# ddr32ss_EMIF_CTLCFG_0F308000h register map
Vendor: Texas Instruments
Registers are 32-bit, read-write, reset 0x0 unless marked. A register's access mark holds for its fields unless they carry their own. Offsets are as the file gives them; [hi:lo] are bit positions; {n}, {i} and the like mark numbered series.

## emif_ctlcfg (part 12 of 13)
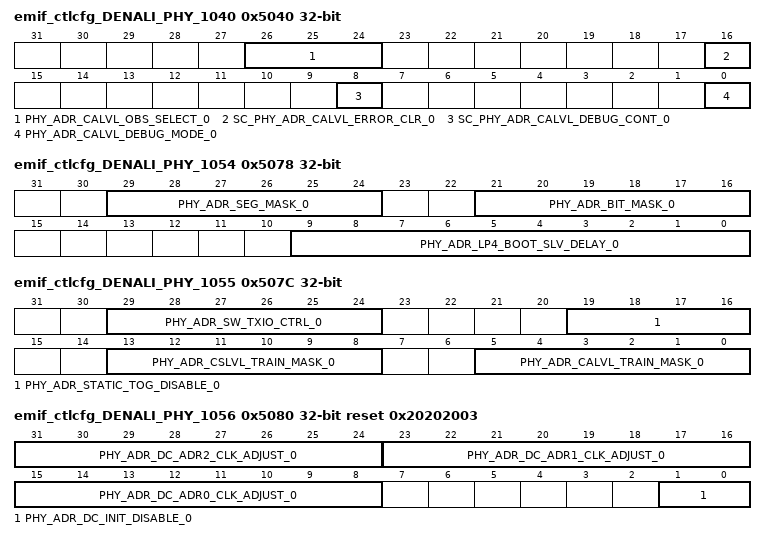
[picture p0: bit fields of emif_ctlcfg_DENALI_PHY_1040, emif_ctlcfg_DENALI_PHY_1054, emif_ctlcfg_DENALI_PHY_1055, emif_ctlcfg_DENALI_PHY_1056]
0x5040 emif_ctlcfg_DENALI_PHY_1040 access per field
  [26:24] PHY_ADR_CALVL_OBS_SELECT_0 rw — CA bit lane to observe result from OBS0 during CA training for address slice 0. Reset Source: ctl_amod_g_rst_n
  [16] SC_PHY_ADR_CALVL_ERROR_CLR_0 wo — Clears the CA training state machine error status for address slice 0. Set to 1 to trigger. WRITE-ONLY Reset Source: ctl_amod_g_rst_n
  [8] SC_PHY_ADR_CALVL_DEBUG_CONT_0 wo — Allows the CA training state machine to advance [when in debug mode] for address slice 0. Set to 1 to trigger. WRITE-ONLY Reset Source: ctl_amod_g_rst_n
  [0] PHY_ADR_CALVL_DEBUG_MODE_0 rw — Enables CA training debug mode for address slice 0. Set to 1 to enable. Reset Source: ctl_amod_g_rst_n
0x5044 emif_ctlcfg_DENALI_PHY_1041 ro
  [31:0] PHY_ADR_CALVL_CH0_OBS0_0 — Observation register for CA training for channel 0 slice 0. READ-ONLY Reset Source: ctl_amod_g_rst_n
0x5048 emif_ctlcfg_DENALI_PHY_1042 ro
  [31:0] PHY_ADR_CALVL_CH1_OBS0_0 — Observation register for CA training for channel 1 slice 0. READ-ONLY Reset Source: ctl_amod_g_rst_n
0x504C emif_ctlcfg_DENALI_PHY_1043 ro
  [31:0] PHY_ADR_CALVL_OBS1_0 — Observation register contains general CA training bits for slice 0. READ-ONLY Reset Source: ctl_amod_g_rst_n
0x5050 emif_ctlcfg_DENALI_PHY_1044 ro reset 0x100
  [31:0] PHY_ADR_CALVL_OBS2_0 — Observation register contains periodic CA training bits for slice 0. READ-ONLY Reset Source: ctl_amod_g_rst_n
0x5054 emif_ctlcfg_DENALI_PHY_1045
  [19:0] PHY_ADR_CALVL_FG_0_0 — CA training foreground pattern 0 for address slice 0. Reset Source: ctl_amod_g_rst_n
0x5058 emif_ctlcfg_DENALI_PHY_1046
  [19:0] PHY_ADR_CALVL_BG_0_0 — CA training background pattern 0 for address slice 0. Reset Source: ctl_amod_g_rst_n
0x505C emif_ctlcfg_DENALI_PHY_1047
  [19:0] PHY_ADR_CALVL_FG_1_0 — CA training foreground pattern 1 for address slice 0. Reset Source: ctl_amod_g_rst_n
0x5060 emif_ctlcfg_DENALI_PHY_1048
  [19:0] PHY_ADR_CALVL_BG_1_0 — CA training background pattern 1 for address slice 0. Reset Source: ctl_amod_g_rst_n
0x5064 emif_ctlcfg_DENALI_PHY_1049
  [19:0] PHY_ADR_CALVL_FG_2_0 — CA training foreground pattern 2 for address slice 0. Reset Source: ctl_amod_g_rst_n
0x5068 emif_ctlcfg_DENALI_PHY_1050
  [19:0] PHY_ADR_CALVL_BG_2_0 — CA training background pattern 2 for address slice 0. Reset Source: ctl_amod_g_rst_n
0x506C emif_ctlcfg_DENALI_PHY_1051
  [19:0] PHY_ADR_CALVL_FG_3_0 — CA training foreground pattern 3 for address slice 0. Reset Source: ctl_amod_g_rst_n
0x5070 emif_ctlcfg_DENALI_PHY_1052
  [19:0] PHY_ADR_CALVL_BG_3_0 — CA training background pattern 3 for address slice 0. Reset Source: ctl_amod_g_rst_n
0x5074 emif_ctlcfg_DENALI_PHY_1053
  [29:0] PHY_ADR_ADDR_SEL_0 — Selects which DFI address pins connect to which CA pins for LPDDR3/4 for address slice 0. Reset Source: ctl_amod_g_rst_n
0x5078 emif_ctlcfg_DENALI_PHY_1054
  [29:24] PHY_ADR_SEG_MASK_0 — Segment mask bit for address slice 0. Set to 1 to indicate that the bit is either CA 4 or CA 9. Reset Source: ctl_amod_g_rst_n
  [21:16] PHY_ADR_BIT_MASK_0 — Mask bit for address slice 0. Set to 1 to indicate that the bit is used. Reset Source: ctl_amod_g_rst_n
  [9:0] PHY_ADR_LP4_BOOT_SLV_DELAY_0 — Address target delay setting during the LPDDR4 boot frequency operation for address slice 0. Reset Source: ctl_amod_g_rst_n
0x507C emif_ctlcfg_DENALI_PHY_1055
  [29:24] PHY_ADR_SW_TXIO_CTRL_0 — Controls address pad output enable for address slice 0. Set to 1 to disable output enable. Reset Source: ctl_amod_g_rst_n
  [19:16] PHY_ADR_STATIC_TOG_DISABLE_0 — Toggle control during static activity for address slice 0. Set bit to dsiable toggling, bit0: Write path delay line, bit1: Read path delay line, bit2: Read data path, bit3: clk_phy, bit4: master delay line. Reset Source: ctl_amod_g_rst_n
  [13:8] PHY_ADR_CSLVL_TRAIN_MASK_0 — Mask bit for CS training participation for address slice 0. Set to 1 to indicate that the bit is participating in CS training. Reset Source: ctl_amod_g_rst_n
  [5:0] PHY_ADR_CALVL_TRAIN_MASK_0 — Mask bit for CA training participation for address slice 0. Set to 1 to indicate that the bit is participating in CA training. Reset Source: ctl_amod_g_rst_n
0x5080 emif_ctlcfg_DENALI_PHY_1056 reset 0x20202003
  [31:24] PHY_ADR_DC_ADR2_CLK_ADJUST_0 — Adjust value of Clock Duty Cycle Adjuster lane 2 for address slice 0. Reset Source: ctl_amod_g_rst_n
  [23:16] PHY_ADR_DC_ADR1_CLK_ADJUST_0 — Adjust value of Clock Duty Cycle Adjuster lane 1 for address slice 0. Reset Source: ctl_amod_g_rst_n
  [15:8] PHY_ADR_DC_ADR0_CLK_ADJUST_0 — Adjust value of Clock Duty Cycle Adjuster lane 0 for address slice 0. Reset Source: ctl_amod_g_rst_n
  [1:0] PHY_ADR_DC_INIT_DISABLE_0 — Duty Cycle Corrector disable at initialization for address slice 0. Set to 1 to disable, bit [1] controls data path, bit [0] controls clock path. Reset Source: ctl_amod_g_rst_n
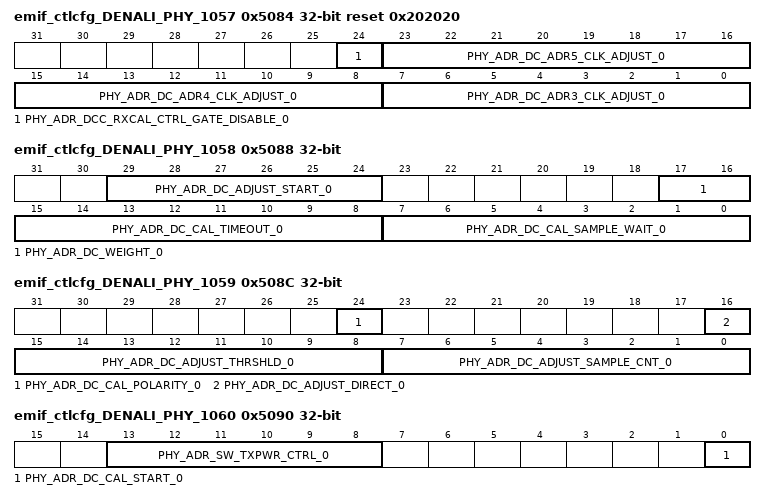
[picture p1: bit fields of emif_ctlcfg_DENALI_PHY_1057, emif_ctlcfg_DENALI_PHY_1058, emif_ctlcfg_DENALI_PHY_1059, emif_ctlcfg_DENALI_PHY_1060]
0x5084 emif_ctlcfg_DENALI_PHY_1057 reset 0x202020
  [24] PHY_ADR_DCC_RXCAL_CTRL_GATE_DISABLE_0 — DCC and RX_CAL clk gate disable for address slice 0. 1 = disable clk gate. Reset Source: ctl_amod_g_rst_n
  [23:16] PHY_ADR_DC_ADR5_CLK_ADJUST_0 — Adjust value of Clock Duty Cycle Adjuster lane 5 for address slice 0. Reset Source: ctl_amod_g_rst_n
  [15:8] PHY_ADR_DC_ADR4_CLK_ADJUST_0 — Adjust value of Clock Duty Cycle Adjuster lane 4 for address slice 0. Reset Source: ctl_amod_g_rst_n
  [7:0] PHY_ADR_DC_ADR3_CLK_ADJUST_0 — Adjust value of Clock Duty Cycle Adjuster lane 3 for address slice 0. Reset Source: ctl_amod_g_rst_n
0x5088 emif_ctlcfg_DENALI_PHY_1058
  [29:24] PHY_ADR_DC_ADJUST_START_0 — DCC calibration starting value for address slice 0. Reset Source: ctl_amod_g_rst_n
  [17:16] PHY_ADR_DC_WEIGHT_0 — DCC weighting factor base value for address slice 0. Reset Source: ctl_amod_g_rst_n
  [15:8] PHY_ADR_DC_CAL_TIMEOUT_0 — DCC number of iterations to wait before timeout for address slice 0. Reset Source: ctl_amod_g_rst_n
  [7:0] PHY_ADR_DC_CAL_SAMPLE_WAIT_0 — DCC cycles to wait after calibration change before sampling results for address slice 0. Reset Source: ctl_amod_g_rst_n
0x508C emif_ctlcfg_DENALI_PHY_1059
  [24] PHY_ADR_DC_CAL_POLARITY_0 — DCC calibration polarity for address slice 0. Reset Source: ctl_amod_g_rst_n
  [16] PHY_ADR_DC_ADJUST_DIRECT_0 — DCC adjust direction for address slice 0. Reset Source: ctl_amod_g_rst_n
  [15:8] PHY_ADR_DC_ADJUST_THRSHLD_0 — DCC adjust threshold around the mid-point for address slice 0. Reset Source: ctl_amod_g_rst_n
  [7:0] PHY_ADR_DC_ADJUST_SAMPLE_CNT_0 — DCC number of samples to take for address slice 0. Reset Source: ctl_amod_g_rst_n
0x5090 emif_ctlcfg_DENALI_PHY_1060
  [13:8] PHY_ADR_SW_TXPWR_CTRL_0 — Disable address output enables in deep sleep mode for address slice 0. Reset Source: ctl_amod_g_rst_n
  [0] PHY_ADR_DC_CAL_START_0 — DCC Manual trigger for address slice 0. Reset Source: ctl_amod_g_rst_n
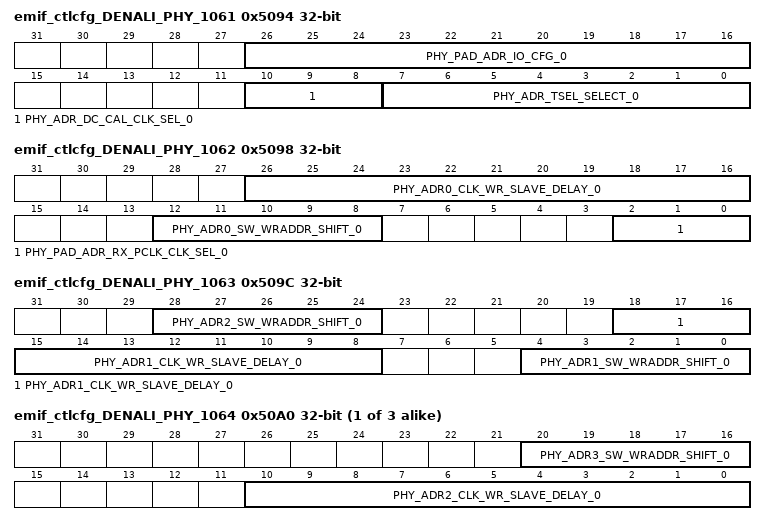
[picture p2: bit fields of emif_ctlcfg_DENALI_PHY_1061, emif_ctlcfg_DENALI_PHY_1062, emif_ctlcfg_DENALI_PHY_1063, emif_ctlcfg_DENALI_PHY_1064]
0x5094 emif_ctlcfg_DENALI_PHY_1061
  [26:16] PHY_PAD_ADR_IO_CFG_0 — Controls I/O pads for address pad for address slice 0. Bits [10:5] = Park value, bits [4] park override, bits [2:0] clk divider. Reset Source: ctl_amod_g_rst_n
  [10:8] PHY_ADR_DC_CAL_CLK_SEL_0 — DCC CAL clock for address slice 0. Reset Source: ctl_amod_g_rst_n
  [7:0] PHY_ADR_TSEL_SELECT_0 — Tsel select values for address slice 0. Reset Source: ctl_amod_g_rst_n
0x5098 emif_ctlcfg_DENALI_PHY_1062
  [26:16] PHY_ADR0_CLK_WR_SLAVE_DELAY_0 — CA bit 0 target delay setting for address slice 0. Reset Source: ctl_amod_g_rst_n
  [12:8] PHY_ADR0_SW_WRADDR_SHIFT_0 — Manual override of CA bit 0 of automatic half_cycle_shift/cycle_shift for address slice 0. Bit [0] enables override of half_cycle_shift. Bit [1] is the half_cycle_shift value. Bit [2] enables override of cycle shift. Bits [4:3] is the cycle_shift value. For bits [4:3], clear to 0x0 for no offset, program to 0x1 for -1 cycle, program to 0x2 for +1 cycle, or program to 0x3 for -2 cycles. Reset Source: ctl_amod_g_rst_n
  [2:0] PHY_PAD_ADR_RX_PCLK_CLK_SEL_0 — Reserved for address slice 0. Reset Source: ctl_amod_g_rst_n
0x509C emif_ctlcfg_DENALI_PHY_1063
  [28:24] PHY_ADR2_SW_WRADDR_SHIFT_0 — Manual override of CA bit 2 of automatic half_cycle_shift/cycle_shift for address slice 0. Bit [0] enables override of half_cycle_shift. Bit [1] is the half_cycle_shift value. Bit [2] enables override of cycle shift. Bits [4:3] is the cycle_shift value. For bits [4:3], clear to 0x0 for no offset, program to 0x1 for -1 cycle, program to 0x2 for +1 cycle, or program to 0x3 for -2 cycles. Reset Source: ctl_amod_g_rst_n
  [18:8] PHY_ADR1_CLK_WR_SLAVE_DELAY_0 — CA bit 1 target delay setting for address slice 0. Reset Source: ctl_amod_g_rst_n
  [4:0] PHY_ADR1_SW_WRADDR_SHIFT_0 — Manual override of CA bit 1 of automatic half_cycle_shift/cycle_shift for address slice 0. Bit [0] enables override of half_cycle_shift. Bit [1] is the half_cycle_shift value. Bit [2] enables override of cycle shift. Bits [4:3] is the cycle_shift value. For bits [4:3], clear to 0x0 for no offset, program to 0x1 for -1 cycle, program to 0x2 for +1 cycle, or program to 0x3 for -2 cycles. Reset Source: ctl_amod_g_rst_n
{0x4000+4i} emif_ctlcfg_DENALI_PHY_{i} (i=1064..1066)
  [20:16] PHY_ADR{i-1061}_SW_WRADDR_SHIFT_0 — Manual override of CA bit {i-1061} of automatic half_cycle_shift/cycle_shift for address slice 0. Bit [0] enables override of half_cycle_shift. Bit [1] is the half_cycle_shift value. Bit [2] enables override of cycle shift. Bits [4:3] is the cycle_shift value. For bits [4:3], clear to 0x0 for no offset, program to 0x1 for -1 cycle, program to 0x2 for +1 cycle, or program to 0x3 for -2 cycles. Reset Source: ctl_amod_g_rst_n
  [10:0] PHY_ADR{i-1062}_CLK_WR_SLAVE_DELAY_0 — CA bit {i-1062} target delay setting for address slice 0. Reset Source: ctl_amod_g_rst_n
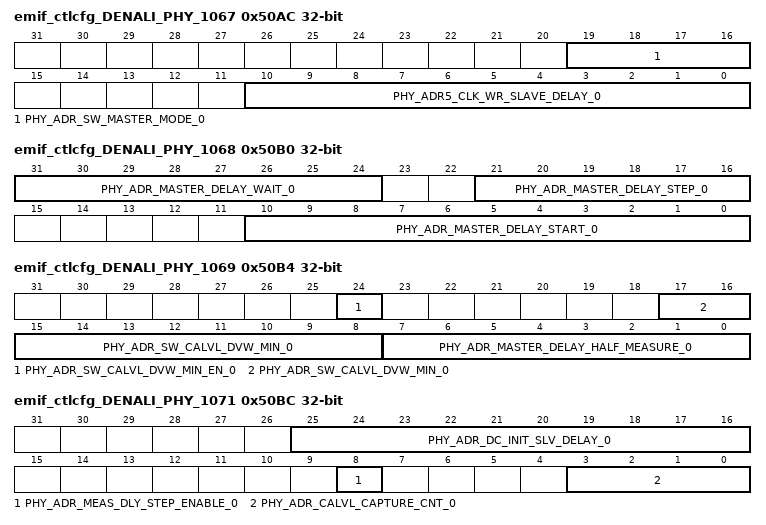
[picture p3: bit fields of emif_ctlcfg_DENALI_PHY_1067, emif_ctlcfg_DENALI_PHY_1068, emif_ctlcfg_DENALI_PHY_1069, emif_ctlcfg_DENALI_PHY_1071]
0x50AC emif_ctlcfg_DENALI_PHY_1067
  [19:16] PHY_ADR_SW_MASTER_MODE_0 — Master delay line override settings for address slice 0. Bit [0] enables software half clock mode. Bit [1] is the software half clock mode value. Bit [2] enables software bypass mode. Bit [3] is the software bypass mode value. Reset Source: ctl_amod_g_rst_n
  [10:0] PHY_ADR5_CLK_WR_SLAVE_DELAY_0 — CA bit 5 target delay setting for address slice 0. Reset Source: ctl_amod_g_rst_n
0x50B0 emif_ctlcfg_DENALI_PHY_1068
  [31:24] PHY_ADR_MASTER_DELAY_WAIT_0 — Wait cycles for master delay line locking algorithm for address slice 0. Bits [3:0] is the cycle wait count after a calibration clock setting change. Bits [7:4] is the cycle wait count after a master delay setting change. Reset Source: ctl_amod_g_rst_n
  [21:16] PHY_ADR_MASTER_DELAY_STEP_0 — Incremental step size for master delay line locking algorithm for address slice 0. Reset Source: ctl_amod_g_rst_n
  [10:0] PHY_ADR_MASTER_DELAY_START_0 — Start value for master delay line locking algorithm for address slice 0. Reset Source: ctl_amod_g_rst_n
0x50B4 emif_ctlcfg_DENALI_PHY_1069
  [24] PHY_ADR_SW_CALVL_DVW_MIN_EN_0 — Enables the software override data valid window size during CA training for address slice 0. Reset Source: ctl_amod_g_rst_n
  [17:8] PHY_ADR_SW_CALVL_DVW_MIN_0 — Sets the software override data valid window size during CA training for address slice 0. Reset Source: ctl_amod_g_rst_n
  [7:0] PHY_ADR_MASTER_DELAY_HALF_MEASURE_0 — Defines the number of delay line elements to be considered in determing whether to lock to a half clock cycle for the master in address slice 0 Reset Source: ctl_amod_g_rst_n
0x50B8 emif_ctlcfg_DENALI_PHY_1070
  [3:0] PHY_ADR_CALVL_DLY_STEP_0 — Sets the delay step size plus 1 during CA training for address slice 0. Reset Source: ctl_amod_g_rst_n
0x50BC emif_ctlcfg_DENALI_PHY_1071
  [25:16] PHY_ADR_DC_INIT_SLV_DELAY_0 — DCC initialization value of write ADDR target delay for address slice 0. Reset Source: ctl_amod_g_rst_n
  [8] PHY_ADR_MEAS_DLY_STEP_ENABLE_0 — Enables delay parameter setting using phy_adr_meas_dly_step_value for address slice 0. Reset Source: ctl_amod_g_rst_n
  [3:0] PHY_ADR_CALVL_CAPTURE_CNT_0 — Number of samples to take at each ADDR target delay setting during CA training for address slice 0. Reset Source: ctl_amod_g_rst_n
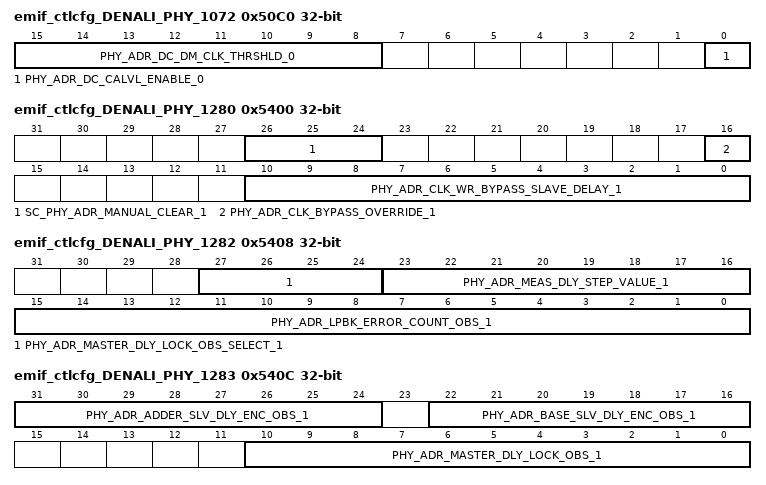
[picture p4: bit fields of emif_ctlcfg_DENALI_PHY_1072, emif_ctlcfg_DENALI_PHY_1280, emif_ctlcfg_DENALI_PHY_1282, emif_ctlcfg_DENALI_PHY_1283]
0x50C0 emif_ctlcfg_DENALI_PHY_1072
  [15:8] PHY_ADR_DC_DM_CLK_THRSHLD_0 — DCC clock measurement cell threshold offset for address slice 0. Reset Source: ctl_amod_g_rst_n
  [0] PHY_ADR_DC_CALVL_ENABLE_0 — DCC enable duty cycle adjust during CA leveling for address slice 0. Reset Source: ctl_amod_g_rst_n
0x5400 emif_ctlcfg_DENALI_PHY_1280 access per field
  [26:24] SC_PHY_ADR_MANUAL_CLEAR_1 wo — Manual reset/clear of internal logic for address slice 1. Bit [0] is reset of master delay min/max lock values. Bit [1] is manual reset of master delay unlock counter. Bit [2] clears the loopback error/results registers. Set each bit to 1 to reset. WRITE-ONLY Reset Source: ctl_amod_g_rst_n
  [16] PHY_ADR_CLK_BYPASS_OVERRIDE_1 rw — Bypass mode override setting for address slice 1. Set to 1 to enable. Reset Source: ctl_amod_g_rst_n
  [10:0] PHY_ADR_CLK_WR_BYPASS_SLAVE_DELAY_1 rw — Command/Address clock bypass mode target delay setting for address slice 1. Reset Source: ctl_amod_g_rst_n
0x5404 emif_ctlcfg_DENALI_PHY_1281 ro reset 0x1000
  [31:0] PHY_ADR_LPBK_RESULT_OBS_1 — Observation register containing loopback status/results for address slice 1. READ-ONLY Reset Source: ctl_amod_g_rst_n
0x5408 emif_ctlcfg_DENALI_PHY_1282 access per field
  [27:24] PHY_ADR_MASTER_DLY_LOCK_OBS_SELECT_1 rw — Select value to map the internal master delay observation registers to the accessible master delay observation register for address slice 1. Reset Source: ctl_amod_g_rst_n
  [23:16] PHY_ADR_MEAS_DLY_STEP_VALUE_1 ro — Contains the fraction of a cycle in 1 delay element numerator with demominator of 512, for address slice 1. READ-ONLY Reset Source: ctl_amod_g_rst_n
  [15:0] PHY_ADR_LPBK_ERROR_COUNT_OBS_1 ro — Observation register containing total number of loopback error data for address slice 1. READ-ONLY Reset Source: ctl_amod_g_rst_n
0x540C emif_ctlcfg_DENALI_PHY_1283 ro
  [31:24] PHY_ADR_ADDER_SLV_DLY_ENC_OBS_1 — Observation register containing addr target delay for address slice 1. READ-ONLY Reset Source: ctl_amod_g_rst_n
  [22:16] PHY_ADR_BASE_SLV_DLY_ENC_OBS_1 — Observation register containing base target delay for address slice 1. READ-ONLY Reset Source: ctl_amod_g_rst_n
  [10:0] PHY_ADR_MASTER_DLY_LOCK_OBS_1 — Observation register containing master delay results for address slice 1. READ-ONLY Reset Source: ctl_amod_g_rst_n
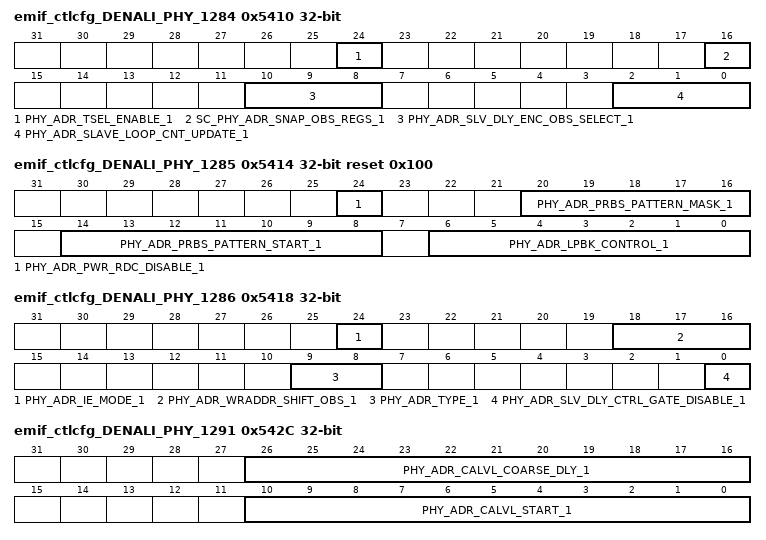
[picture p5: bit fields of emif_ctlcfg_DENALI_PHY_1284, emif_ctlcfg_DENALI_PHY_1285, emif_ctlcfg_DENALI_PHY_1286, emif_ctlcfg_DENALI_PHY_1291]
0x5410 emif_ctlcfg_DENALI_PHY_1284 access per field
  [24] PHY_ADR_TSEL_ENABLE_1 rw — Enables tsel_en for address slice 1. Reset Source: ctl_amod_g_rst_n
  [16] SC_PHY_ADR_SNAP_OBS_REGS_1 wo — Initiates a snapshot of the internal observation registers for address slice 1. Set to 1 to trigger. WRITE-ONLY Reset Source: ctl_amod_g_rst_n
  [10:8] PHY_ADR_SLV_DLY_ENC_OBS_SELECT_1 rw — Select value to map the addr bits delay observation registers to the accessible delay observation register for address slice 1. Reset Source: ctl_amod_g_rst_n
  [2:0] PHY_ADR_SLAVE_LOOP_CNT_UPDATE_1 rw — Reserved for address slice 1. Reset Source: ctl_amod_g_rst_n
0x5414 emif_ctlcfg_DENALI_PHY_1285 reset 0x100
  [24] PHY_ADR_PWR_RDC_DISABLE_1 — Power reduction disable for address slice 1. Reset Source: ctl_amod_g_rst_n
  [20:16] PHY_ADR_PRBS_PATTERN_MASK_1 — PRBS7 mask signal for address slice 1. Reset Source: ctl_amod_g_rst_n
  [14:8] PHY_ADR_PRBS_PATTERN_START_1 — PRBS7 start pattern for address slice 1. Reset Source: ctl_amod_g_rst_n
  [6:0] PHY_ADR_LPBK_CONTROL_1 — Loopback control bits for address slice 1. Reset Source: ctl_amod_g_rst_n
0x5418 emif_ctlcfg_DENALI_PHY_1286 access per field
  [24] PHY_ADR_IE_MODE_1 rw — Input enable control for address slice 1. Reset Source: ctl_amod_g_rst_n
  [18:16] PHY_ADR_WRADDR_SHIFT_OBS_1 ro — Observation register containing automatic half cycle and cycle shift values for address slice 1. READ-ONLY Reset Source: ctl_amod_g_rst_n
  [9:8] PHY_ADR_TYPE_1 rw — DRAM type for address slice 1. Reset Source: ctl_amod_g_rst_n
  [0] PHY_ADR_SLV_DLY_CTRL_GATE_DISABLE_1 rw — Power reduction slv_dly_control block gate disable for address slice 1. Reset Source: ctl_amod_g_rst_n
0x541C emif_ctlcfg_DENALI_PHY_1287
  [26:0] PHY_ADR_DDL_MODE_1 — DDL mode for address slice 1. Reset Source: ctl_amod_g_rst_n
0x5420 emif_ctlcfg_DENALI_PHY_1288
  [5:0] PHY_ADR_DDL_MASK_1 — DDL mask for address slice 1. Reset Source: ctl_amod_g_rst_n
0x5424 emif_ctlcfg_DENALI_PHY_1289 ro
  [31:0] PHY_ADR_DDL_TEST_OBS_1 — Observation register containing DDL test bits for address slice 1. READ-ONLY Reset Source: ctl_amod_g_rst_n
0x5428 emif_ctlcfg_DENALI_PHY_1290 ro
  [31:0] PHY_ADR_DDL_TEST_MSTR_DLY_OBS_1 — Observation register containing master DDL bits for address slice 1. READ-ONLY Reset Source: ctl_amod_g_rst_n
0x542C emif_ctlcfg_DENALI_PHY_1291
  [26:16] PHY_ADR_CALVL_COARSE_DLY_1 — Coarse CA training DDL increment value for address slice 1. Reset Source: ctl_amod_g_rst_n
  [10:0] PHY_ADR_CALVL_START_1 — CA training DDL start value for address slice 1. Reset Source: ctl_amod_g_rst_n
0x5430 emif_ctlcfg_DENALI_PHY_1292
  [10:0] PHY_ADR_CALVL_QTR_1 — CA training DDL quarter cycle delay value for address slice 1. Reset Source: ctl_amod_g_rst_n
0x5434 emif_ctlcfg_DENALI_PHY_1293
  [23:0] PHY_ADR_CALVL_SWIZZLE0_1 — CA training RD DQ bit swizzle map 0 for address slice 1. Reset Source: ctl_amod_g_rst_n
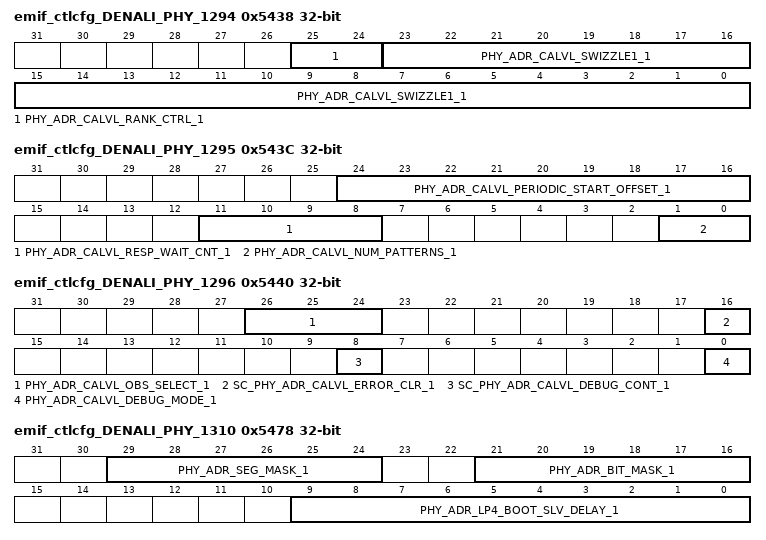
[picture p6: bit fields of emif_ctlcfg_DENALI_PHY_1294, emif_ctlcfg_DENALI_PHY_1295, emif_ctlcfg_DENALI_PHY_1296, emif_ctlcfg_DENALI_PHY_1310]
0x5438 emif_ctlcfg_DENALI_PHY_1294
  [25:24] PHY_ADR_CALVL_RANK_CTRL_1 — CA training rank aggregation control bits for address slice 1. Reset Source: ctl_amod_g_rst_n
  [23:0] PHY_ADR_CALVL_SWIZZLE1_1 — CA training RD DQ bit swizzle map 1 for address slice 1. Reset Source: ctl_amod_g_rst_n
0x543C emif_ctlcfg_DENALI_PHY_1295
  [24:16] PHY_ADR_CALVL_PERIODIC_START_OFFSET_1 — Relative offset to start periodic CALVL from previous result Reset Source: ctl_amod_g_rst_n
  [11:8] PHY_ADR_CALVL_RESP_WAIT_CNT_1 — Number of samples to wait before sampling response during CA training for address slice 1. Reset Source: ctl_amod_g_rst_n
  [1:0] PHY_ADR_CALVL_NUM_PATTERNS_1 — Number of patterns to use during CA training for address slice 1. Reset Source: ctl_amod_g_rst_n
0x5440 emif_ctlcfg_DENALI_PHY_1296 access per field
  [26:24] PHY_ADR_CALVL_OBS_SELECT_1 rw — CA bit lane to observe result from OBS0 during CA training for address slice 1. Reset Source: ctl_amod_g_rst_n
  [16] SC_PHY_ADR_CALVL_ERROR_CLR_1 wo — Clears the CA training state machine error status for address slice 1. Set to 1 to trigger. WRITE-ONLY Reset Source: ctl_amod_g_rst_n
  [8] SC_PHY_ADR_CALVL_DEBUG_CONT_1 wo — Allows the CA training state machine to advance [when in debug mode] for address slice 1. Set to 1 to trigger. WRITE-ONLY Reset Source: ctl_amod_g_rst_n
  [0] PHY_ADR_CALVL_DEBUG_MODE_1 rw — Enables CA training debug mode for address slice 1. Set to 1 to enable. Reset Source: ctl_amod_g_rst_n
0x5444 emif_ctlcfg_DENALI_PHY_1297 ro
  [31:0] PHY_ADR_CALVL_CH0_OBS0_1 — Observation register for CA training for channel 0 slice 1. READ-ONLY Reset Source: ctl_amod_g_rst_n
0x5448 emif_ctlcfg_DENALI_PHY_1298 ro
  [31:0] PHY_ADR_CALVL_CH1_OBS0_1 — Observation register for CA training for channel 1 slice 1. READ-ONLY Reset Source: ctl_amod_g_rst_n
0x544C emif_ctlcfg_DENALI_PHY_1299 ro
  [31:0] PHY_ADR_CALVL_OBS1_1 — Observation register contains general CA training bits for slice 1. READ-ONLY Reset Source: ctl_amod_g_rst_n
0x5450 emif_ctlcfg_DENALI_PHY_1300 ro reset 0x100
  [31:0] PHY_ADR_CALVL_OBS2_1 — Observation register contains periodic CA training bits for slice 1. READ-ONLY Reset Source: ctl_amod_g_rst_n
0x5454 emif_ctlcfg_DENALI_PHY_1301
  [19:0] PHY_ADR_CALVL_FG_0_1 — CA training foreground pattern 0 for address slice 1. Reset Source: ctl_amod_g_rst_n
0x5458 emif_ctlcfg_DENALI_PHY_1302
  [19:0] PHY_ADR_CALVL_BG_0_1 — CA training background pattern 0 for address slice 1. Reset Source: ctl_amod_g_rst_n
0x545C emif_ctlcfg_DENALI_PHY_1303
  [19:0] PHY_ADR_CALVL_FG_1_1 — CA training foreground pattern 1 for address slice 1. Reset Source: ctl_amod_g_rst_n
0x5460 emif_ctlcfg_DENALI_PHY_1304
  [19:0] PHY_ADR_CALVL_BG_1_1 — CA training background pattern 1 for address slice 1. Reset Source: ctl_amod_g_rst_n
0x5464 emif_ctlcfg_DENALI_PHY_1305
  [19:0] PHY_ADR_CALVL_FG_2_1 — CA training foreground pattern 2 for address slice 1. Reset Source: ctl_amod_g_rst_n
0x5468 emif_ctlcfg_DENALI_PHY_1306
  [19:0] PHY_ADR_CALVL_BG_2_1 — CA training background pattern 2 for address slice 1. Reset Source: ctl_amod_g_rst_n
0x546C emif_ctlcfg_DENALI_PHY_1307
  [19:0] PHY_ADR_CALVL_FG_3_1 — CA training foreground pattern 3 for address slice 1. Reset Source: ctl_amod_g_rst_n
0x5470 emif_ctlcfg_DENALI_PHY_1308
  [19:0] PHY_ADR_CALVL_BG_3_1 — CA training background pattern 3 for address slice 1. Reset Source: ctl_amod_g_rst_n
0x5474 emif_ctlcfg_DENALI_PHY_1309
  [29:0] PHY_ADR_ADDR_SEL_1 — Selects which DFI address pins connect to which CA pins for LPDDR3/4 for address slice 1. Reset Source: ctl_amod_g_rst_n
0x5478 emif_ctlcfg_DENALI_PHY_1310
  [29:24] PHY_ADR_SEG_MASK_1 — Segment mask bit for address slice 1. Set to 1 to indicate that the bit is either CA 4 or CA 9. Reset Source: ctl_amod_g_rst_n
  [21:16] PHY_ADR_BIT_MASK_1 — Mask bit for address slice 1. Set to 1 to indicate that the bit is used. Reset Source: ctl_amod_g_rst_n
  [9:0] PHY_ADR_LP4_BOOT_SLV_DELAY_1 — Address target delay setting during the LPDDR4 boot frequency operation for address slice 1. Reset Source: ctl_amod_g_rst_n
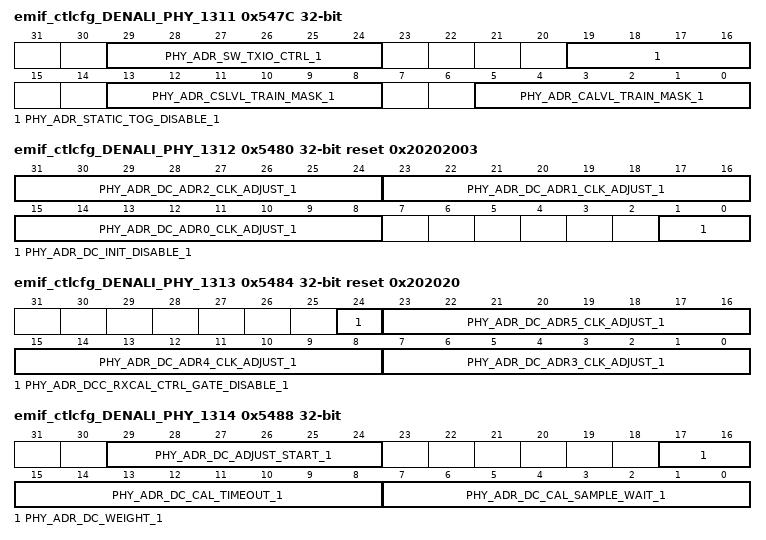
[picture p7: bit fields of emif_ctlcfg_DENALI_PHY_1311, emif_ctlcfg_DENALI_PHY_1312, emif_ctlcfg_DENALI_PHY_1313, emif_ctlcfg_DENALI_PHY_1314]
0x547C emif_ctlcfg_DENALI_PHY_1311
  [29:24] PHY_ADR_SW_TXIO_CTRL_1 — Controls address pad output enable for address slice 1. Set to 1 to disable output enable. Reset Source: ctl_amod_g_rst_n
  [19:16] PHY_ADR_STATIC_TOG_DISABLE_1 — Toggle control during static activity for address slice 1. Set bit to dsiable toggling, bit0: Write path delay line, bit1: Read path delay line, bit2: Read data path, bit3: clk_phy, bit4: master delay line. Reset Source: ctl_amod_g_rst_n
  [13:8] PHY_ADR_CSLVL_TRAIN_MASK_1 — Mask bit for CS training participation for address slice 1. Set to 1 to indicate that the bit is participating in CS training. Reset Source: ctl_amod_g_rst_n
  [5:0] PHY_ADR_CALVL_TRAIN_MASK_1 — Mask bit for CA training participation for address slice 1. Set to 1 to indicate that the bit is participating in CA training. Reset Source: ctl_amod_g_rst_n
0x5480 emif_ctlcfg_DENALI_PHY_1312 reset 0x20202003
  [31:24] PHY_ADR_DC_ADR2_CLK_ADJUST_1 — Adjust value of Clock Duty Cycle Adjuster lane 2 for address slice 1. Reset Source: ctl_amod_g_rst_n
  [23:16] PHY_ADR_DC_ADR1_CLK_ADJUST_1 — Adjust value of Clock Duty Cycle Adjuster lane 1 for address slice 1. Reset Source: ctl_amod_g_rst_n
  [15:8] PHY_ADR_DC_ADR0_CLK_ADJUST_1 — Adjust value of Clock Duty Cycle Adjuster lane 0 for address slice 1. Reset Source: ctl_amod_g_rst_n
  [1:0] PHY_ADR_DC_INIT_DISABLE_1 — Duty Cycle Corrector disable at initialization for address slice 1. Set to 1 to disable, bit [1] controls data path, bit [0] controls clock path. Reset Source: ctl_amod_g_rst_n
0x5484 emif_ctlcfg_DENALI_PHY_1313 reset 0x202020
  [24] PHY_ADR_DCC_RXCAL_CTRL_GATE_DISABLE_1 — DCC and RX_CAL clk gate disable for address slice 1. 1 = disable clk gate. Reset Source: ctl_amod_g_rst_n
  [23:16] PHY_ADR_DC_ADR5_CLK_ADJUST_1 — Adjust value of Clock Duty Cycle Adjuster lane 5 for address slice 1. Reset Source: ctl_amod_g_rst_n
  [15:8] PHY_ADR_DC_ADR4_CLK_ADJUST_1 — Adjust value of Clock Duty Cycle Adjuster lane 4 for address slice 1. Reset Source: ctl_amod_g_rst_n
  [7:0] PHY_ADR_DC_ADR3_CLK_ADJUST_1 — Adjust value of Clock Duty Cycle Adjuster lane 3 for address slice 1. Reset Source: ctl_amod_g_rst_n
0x5488 emif_ctlcfg_DENALI_PHY_1314
  [29:24] PHY_ADR_DC_ADJUST_START_1 — DCC calibration starting value for address slice 1. Reset Source: ctl_amod_g_rst_n
  [17:16] PHY_ADR_DC_WEIGHT_1 — DCC weighting factor base value for address slice 1. Reset Source: ctl_amod_g_rst_n
  [15:8] PHY_ADR_DC_CAL_TIMEOUT_1 — DCC number of iterations to wait before timeout for address slice 1. Reset Source: ctl_amod_g_rst_n
  [7:0] PHY_ADR_DC_CAL_SAMPLE_WAIT_1 — DCC cycles to wait after calibration change before sampling results for address slice 1. Reset Source: ctl_amod_g_rst_n
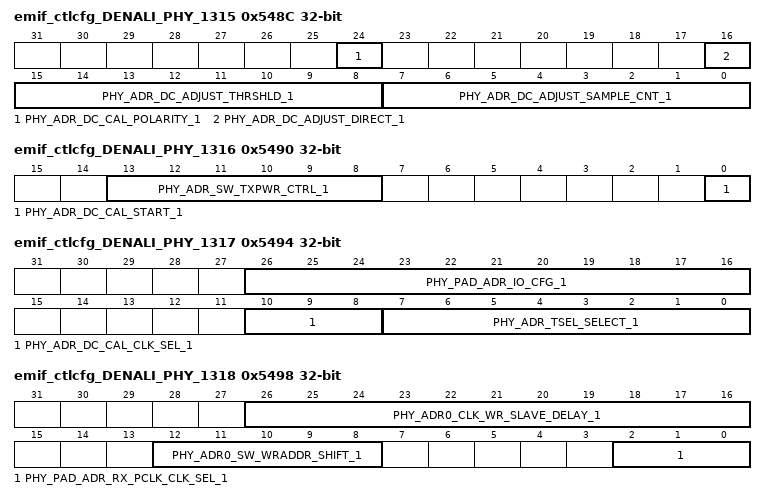
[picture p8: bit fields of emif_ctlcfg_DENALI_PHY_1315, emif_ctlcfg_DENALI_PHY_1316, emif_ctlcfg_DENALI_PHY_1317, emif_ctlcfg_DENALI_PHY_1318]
0x548C emif_ctlcfg_DENALI_PHY_1315
  [24] PHY_ADR_DC_CAL_POLARITY_1 — DCC calibration polarity for address slice 1. Reset Source: ctl_amod_g_rst_n
  [16] PHY_ADR_DC_ADJUST_DIRECT_1 — DCC adjust direction for address slice 1. Reset Source: ctl_amod_g_rst_n
  [15:8] PHY_ADR_DC_ADJUST_THRSHLD_1 — DCC adjust threshold around the mid-point for address slice 1. Reset Source: ctl_amod_g_rst_n
  [7:0] PHY_ADR_DC_ADJUST_SAMPLE_CNT_1 — DCC number of samples to take for address slice 1. Reset Source: ctl_amod_g_rst_n
0x5490 emif_ctlcfg_DENALI_PHY_1316
  [13:8] PHY_ADR_SW_TXPWR_CTRL_1 — Disable address output enables in deep sleep mode for address slice 1. Reset Source: ctl_amod_g_rst_n
  [0] PHY_ADR_DC_CAL_START_1 — DCC Manual trigger for address slice 1. Reset Source: ctl_amod_g_rst_n
0x5494 emif_ctlcfg_DENALI_PHY_1317
  [26:16] PHY_PAD_ADR_IO_CFG_1 — Controls I/O pads for address pad for address slice 1. Bits [10:5] = Park value, bits [4] park override, bits [2:0] clk divider. Reset Source: ctl_amod_g_rst_n
  [10:8] PHY_ADR_DC_CAL_CLK_SEL_1 — DCC CAL clock for address slice 1. Reset Source: ctl_amod_g_rst_n
  [7:0] PHY_ADR_TSEL_SELECT_1 — Tsel select values for address slice 1. Reset Source: ctl_amod_g_rst_n
0x5498 emif_ctlcfg_DENALI_PHY_1318
  [26:16] PHY_ADR0_CLK_WR_SLAVE_DELAY_1 — CA bit 0 target delay setting for address slice 1. Reset Source: ctl_amod_g_rst_n
  [12:8] PHY_ADR0_SW_WRADDR_SHIFT_1 — Manual override of CA bit 0 of automatic half_cycle_shift/cycle_shift for address slice 1. Bit [0] enables override of half_cycle_shift. Bit [1] is the half_cycle_shift value. Bit [2] enables override of cycle shift. Bits [4:3] is the cycle_shift value. For bits [4:3], clear to 0x0 for no offset, program to 0x1 for -1 cycle, program to 0x2 for +1 cycle, or program to 0x3 for -2 cycles. Reset Source: ctl_amod_g_rst_n
  [2:0] PHY_PAD_ADR_RX_PCLK_CLK_SEL_1 — Reserved for address slice 1. Reset Source: ctl_amod_g_rst_n
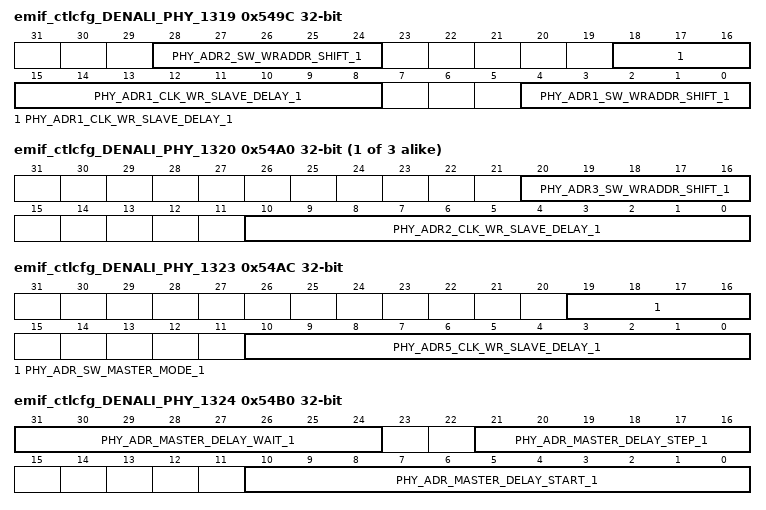
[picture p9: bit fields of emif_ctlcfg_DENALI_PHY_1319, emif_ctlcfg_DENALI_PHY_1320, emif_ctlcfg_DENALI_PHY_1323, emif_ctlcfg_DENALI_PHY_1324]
0x549C emif_ctlcfg_DENALI_PHY_1319
  [28:24] PHY_ADR2_SW_WRADDR_SHIFT_1 — Manual override of CA bit 2 of automatic half_cycle_shift/cycle_shift for address slice 1. Bit [0] enables override of half_cycle_shift. Bit [1] is the half_cycle_shift value. Bit [2] enables override of cycle shift. Bits [4:3] is the cycle_shift value. For bits [4:3], clear to 0x0 for no offset, program to 0x1 for -1 cycle, program to 0x2 for +1 cycle, or program to 0x3 for -2 cycles. Reset Source: ctl_amod_g_rst_n
  [18:8] PHY_ADR1_CLK_WR_SLAVE_DELAY_1 — CA bit 1 target delay setting for address slice 1. Reset Source: ctl_amod_g_rst_n
  [4:0] PHY_ADR1_SW_WRADDR_SHIFT_1 — Manual override of CA bit 1 of automatic half_cycle_shift/cycle_shift for address slice 1. Bit [0] enables override of half_cycle_shift. Bit [1] is the half_cycle_shift value. Bit [2] enables override of cycle shift. Bits [4:3] is the cycle_shift value. For bits [4:3], clear to 0x0 for no offset, program to 0x1 for -1 cycle, program to 0x2 for +1 cycle, or program to 0x3 for -2 cycles. Reset Source: ctl_amod_g_rst_n
{0x4000+4i} emif_ctlcfg_DENALI_PHY_{i} (i=1320..1322)
  [20:16] PHY_ADR{i-1317}_SW_WRADDR_SHIFT_1 — Manual override of CA bit {i-1317} of automatic half_cycle_shift/cycle_shift for address slice 1. Bit [0] enables override of half_cycle_shift. Bit [1] is the half_cycle_shift value. Bit [2] enables override of cycle shift. Bits [4:3] is the cycle_shift value. For bits [4:3], clear to 0x0 for no offset, program to 0x1 for -1 cycle, program to 0x2 for +1 cycle, or program to 0x3 for -2 cycles. Reset Source: ctl_amod_g_rst_n
  [10:0] PHY_ADR{i-1318}_CLK_WR_SLAVE_DELAY_1 — CA bit {i-1318} target delay setting for address slice 1. Reset Source: ctl_amod_g_rst_n
0x54AC emif_ctlcfg_DENALI_PHY_1323
  [19:16] PHY_ADR_SW_MASTER_MODE_1 — Master delay line override settings for address slice 1. Bit [0] enables software half clock mode. Bit [1] is the software half clock mode value. Bit [2] enables software bypass mode. Bit [3] is the software bypass mode value. Reset Source: ctl_amod_g_rst_n
  [10:0] PHY_ADR5_CLK_WR_SLAVE_DELAY_1 — CA bit 5 target delay setting for address slice 1. Reset Source: ctl_amod_g_rst_n
0x54B0 emif_ctlcfg_DENALI_PHY_1324
  [31:24] PHY_ADR_MASTER_DELAY_WAIT_1 — Wait cycles for master delay line locking algorithm for address slice 1. Bits [3:0] is the cycle wait count after a calibration clock setting change. Bits [7:4] is the cycle wait count after a master delay setting change. Reset Source: ctl_amod_g_rst_n
  [21:16] PHY_ADR_MASTER_DELAY_STEP_1 — Incremental step size for master delay line locking algorithm for address slice 1. Reset Source: ctl_amod_g_rst_n
  [10:0] PHY_ADR_MASTER_DELAY_START_1 — Start value for master delay line locking algorithm for address slice 1. Reset Source: ctl_amod_g_rst_n
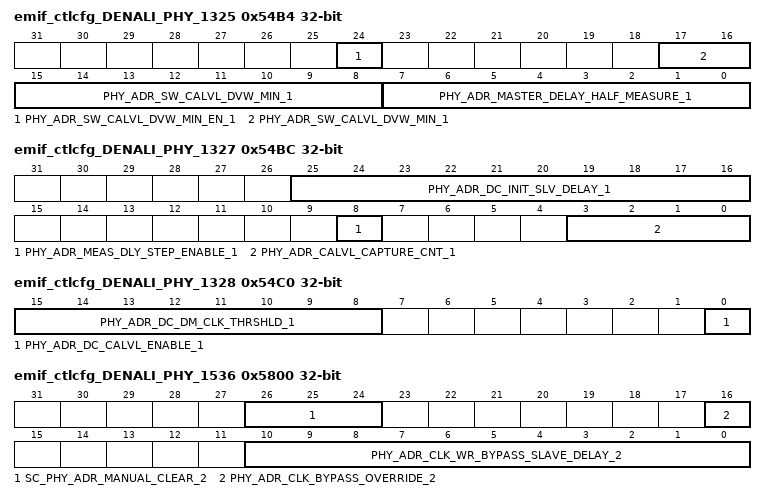
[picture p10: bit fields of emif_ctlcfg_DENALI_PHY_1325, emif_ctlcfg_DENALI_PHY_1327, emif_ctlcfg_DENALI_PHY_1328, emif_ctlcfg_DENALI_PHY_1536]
0x54B4 emif_ctlcfg_DENALI_PHY_1325
  [24] PHY_ADR_SW_CALVL_DVW_MIN_EN_1 — Enables the software override data valid window size during CA training for address slice 1. Reset Source: ctl_amod_g_rst_n
  [17:8] PHY_ADR_SW_CALVL_DVW_MIN_1 — Sets the software override data valid window size during CA training for address slice 1. Reset Source: ctl_amod_g_rst_n
  [7:0] PHY_ADR_MASTER_DELAY_HALF_MEASURE_1 — Defines the number of delay line elements to be considered in determing whether to lock to a half clock cycle for the master in address slice 1 Reset Source: ctl_amod_g_rst_n
0x54B8 emif_ctlcfg_DENALI_PHY_1326
  [3:0] PHY_ADR_CALVL_DLY_STEP_1 — Sets the delay step size plus 1 during CA training for address slice 1. Reset Source: ctl_amod_g_rst_n
0x54BC emif_ctlcfg_DENALI_PHY_1327
  [25:16] PHY_ADR_DC_INIT_SLV_DELAY_1 — DCC initialization value of write ADDR target delay for address slice 1. Reset Source: ctl_amod_g_rst_n
  [8] PHY_ADR_MEAS_DLY_STEP_ENABLE_1 — Enables delay parameter setting using phy_adr_meas_dly_step_value for address slice 1. Reset Source: ctl_amod_g_rst_n
  [3:0] PHY_ADR_CALVL_CAPTURE_CNT_1 — Number of samples to take at each ADDR target delay setting during CA training for address slice 1. Reset Source: ctl_amod_g_rst_n
0x54C0 emif_ctlcfg_DENALI_PHY_1328
  [15:8] PHY_ADR_DC_DM_CLK_THRSHLD_1 — DCC clock measurement cell threshold offset for address slice 1. Reset Source: ctl_amod_g_rst_n
  [0] PHY_ADR_DC_CALVL_ENABLE_1 — DCC enable duty cycle adjust during CA leveling for address slice 1. Reset Source: ctl_amod_g_rst_n
0x5800 emif_ctlcfg_DENALI_PHY_1536 access per field
  [26:24] SC_PHY_ADR_MANUAL_CLEAR_2 wo — Manual reset/clear of internal logic for address slice 2. Bit [0] is reset of master delay min/max lock values. Bit [1] is manual reset of master delay unlock counter. Bit [2] clears the loopback error/results registers. Set each bit to 1 to reset. WRITE-ONLY Reset Source: ctl_amod_g_rst_n
  [16] PHY_ADR_CLK_BYPASS_OVERRIDE_2 rw — Bypass mode override setting for address slice 2. Set to 1 to enable. Reset Source: ctl_amod_g_rst_n
  [10:0] PHY_ADR_CLK_WR_BYPASS_SLAVE_DELAY_2 rw — Command/Address clock bypass mode target delay setting for address slice 2. Reset Source: ctl_amod_g_rst_n
0x5804 emif_ctlcfg_DENALI_PHY_1537 ro reset 0x1000
  [31:0] PHY_ADR_LPBK_RESULT_OBS_2 — Observation register containing loopback status/results for address slice 2. READ-ONLY Reset Source: ctl_amod_g_rst_n
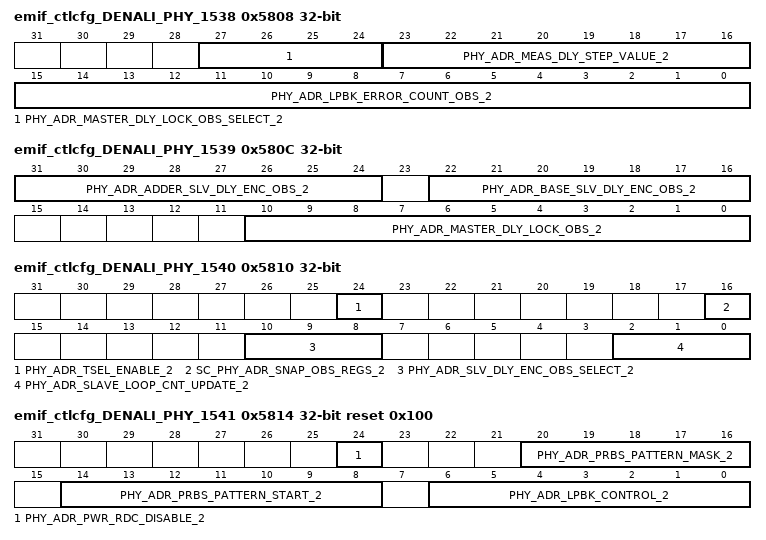
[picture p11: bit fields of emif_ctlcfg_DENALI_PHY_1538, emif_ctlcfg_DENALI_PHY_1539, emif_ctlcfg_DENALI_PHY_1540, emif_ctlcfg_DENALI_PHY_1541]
0x5808 emif_ctlcfg_DENALI_PHY_1538 access per field
  [27:24] PHY_ADR_MASTER_DLY_LOCK_OBS_SELECT_2 rw — Select value to map the internal master delay observation registers to the accessible master delay observation register for address slice 2. Reset Source: ctl_amod_g_rst_n
  [23:16] PHY_ADR_MEAS_DLY_STEP_VALUE_2 ro — Contains the fraction of a cycle in 1 delay element numerator with demominator of 512, for address slice 2. READ-ONLY Reset Source: ctl_amod_g_rst_n
  [15:0] PHY_ADR_LPBK_ERROR_COUNT_OBS_2 ro — Observation register containing total number of loopback error data for address slice 2. READ-ONLY Reset Source: ctl_amod_g_rst_n
0x580C emif_ctlcfg_DENALI_PHY_1539 ro
  [31:24] PHY_ADR_ADDER_SLV_DLY_ENC_OBS_2 — Observation register containing addr target delay for address slice 2. READ-ONLY Reset Source: ctl_amod_g_rst_n
  [22:16] PHY_ADR_BASE_SLV_DLY_ENC_OBS_2 — Observation register containing base target delay for address slice 2. READ-ONLY Reset Source: ctl_amod_g_rst_n
  [10:0] PHY_ADR_MASTER_DLY_LOCK_OBS_2 — Observation register containing master delay results for address slice 2. READ-ONLY Reset Source: ctl_amod_g_rst_n
0x5810 emif_ctlcfg_DENALI_PHY_1540 access per field
  [24] PHY_ADR_TSEL_ENABLE_2 rw — Enables tsel_en for address slice 2. Reset Source: ctl_amod_g_rst_n
  [16] SC_PHY_ADR_SNAP_OBS_REGS_2 wo — Initiates a snapshot of the internal observation registers for address slice 2. Set to 1 to trigger. WRITE-ONLY Reset Source: ctl_amod_g_rst_n
  [10:8] PHY_ADR_SLV_DLY_ENC_OBS_SELECT_2 rw — Select value to map the addr bits delay observation registers to the accessible delay observation register for address slice 2. Reset Source: ctl_amod_g_rst_n
  [2:0] PHY_ADR_SLAVE_LOOP_CNT_UPDATE_2 rw — Reserved for address slice 2. Reset Source: ctl_amod_g_rst_n
0x5814 emif_ctlcfg_DENALI_PHY_1541 reset 0x100
  [24] PHY_ADR_PWR_RDC_DISABLE_2 — Power reduction disable for address slice 2. Reset Source: ctl_amod_g_rst_n
  [20:16] PHY_ADR_PRBS_PATTERN_MASK_2 — PRBS7 mask signal for address slice 2. Reset Source: ctl_amod_g_rst_n
  [14:8] PHY_ADR_PRBS_PATTERN_START_2 — PRBS7 start pattern for address slice 2. Reset Source: ctl_amod_g_rst_n
  [6:0] PHY_ADR_LPBK_CONTROL_2 — Loopback control bits for address slice 2. Reset Source: ctl_amod_g_rst_n
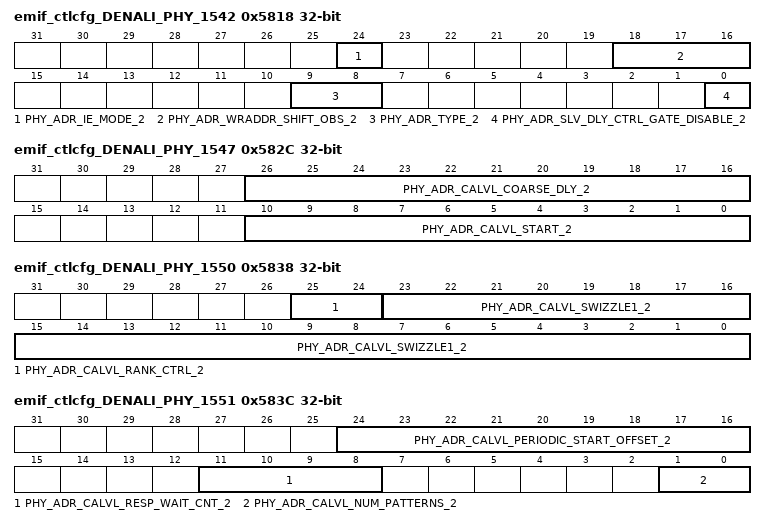
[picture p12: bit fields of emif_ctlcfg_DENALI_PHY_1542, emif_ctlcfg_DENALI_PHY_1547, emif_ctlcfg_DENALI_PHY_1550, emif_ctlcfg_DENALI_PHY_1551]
0x5818 emif_ctlcfg_DENALI_PHY_1542 access per field
  [24] PHY_ADR_IE_MODE_2 rw — Input enable control for address slice 2. Reset Source: ctl_amod_g_rst_n
  [18:16] PHY_ADR_WRADDR_SHIFT_OBS_2 ro — Observation register containing automatic half cycle and cycle shift values for address slice 2. READ-ONLY Reset Source: ctl_amod_g_rst_n
  [9:8] PHY_ADR_TYPE_2 rw — DRAM type for address slice 2. Reset Source: ctl_amod_g_rst_n
  [0] PHY_ADR_SLV_DLY_CTRL_GATE_DISABLE_2 rw — Power reduction slv_dly_control block gate disable for address slice 2. Reset Source: ctl_amod_g_rst_n
0x581C emif_ctlcfg_DENALI_PHY_1543
  [26:0] PHY_ADR_DDL_MODE_2 — DDL mode for address slice 2. Reset Source: ctl_amod_g_rst_n
0x5820 emif_ctlcfg_DENALI_PHY_1544
  [5:0] PHY_ADR_DDL_MASK_2 — DDL mask for address slice 2. Reset Source: ctl_amod_g_rst_n
0x5824 emif_ctlcfg_DENALI_PHY_1545 ro
  [31:0] PHY_ADR_DDL_TEST_OBS_2 — Observation register containing DDL test bits for address slice 2. READ-ONLY Reset Source: ctl_amod_g_rst_n
0x5828 emif_ctlcfg_DENALI_PHY_1546 ro
  [31:0] PHY_ADR_DDL_TEST_MSTR_DLY_OBS_2 — Observation register containing master DDL bits for address slice 2. READ-ONLY Reset Source: ctl_amod_g_rst_n
0x582C emif_ctlcfg_DENALI_PHY_1547
  [26:16] PHY_ADR_CALVL_COARSE_DLY_2 — Coarse CA training DDL increment value for address slice 2. Reset Source: ctl_amod_g_rst_n
  [10:0] PHY_ADR_CALVL_START_2 — CA training DDL start value for address slice 2. Reset Source: ctl_amod_g_rst_n
0x5830 emif_ctlcfg_DENALI_PHY_1548
  [10:0] PHY_ADR_CALVL_QTR_2 — CA training DDL quarter cycle delay value for address slice 2. Reset Source: ctl_amod_g_rst_n
0x5834 emif_ctlcfg_DENALI_PHY_1549
  [23:0] PHY_ADR_CALVL_SWIZZLE0_2 — CA training RD DQ bit swizzle map 0 for address slice 2. Reset Source: ctl_amod_g_rst_n
0x5838 emif_ctlcfg_DENALI_PHY_1550
  [25:24] PHY_ADR_CALVL_RANK_CTRL_2 — CA training rank aggregation control bits for address slice 2. Reset Source: ctl_amod_g_rst_n
  [23:0] PHY_ADR_CALVL_SWIZZLE1_2 — CA training RD DQ bit swizzle map 1 for address slice 2. Reset Source: ctl_amod_g_rst_n
0x583C emif_ctlcfg_DENALI_PHY_1551
  [24:16] PHY_ADR_CALVL_PERIODIC_START_OFFSET_2 — Relative offset to start periodic CALVL from previous result Reset Source: ctl_amod_g_rst_n
  [11:8] PHY_ADR_CALVL_RESP_WAIT_CNT_2 — Number of samples to wait before sampling response during CA training for address slice 2. Reset Source: ctl_amod_g_rst_n
  [1:0] PHY_ADR_CALVL_NUM_PATTERNS_2 — Number of patterns to use during CA training for address slice 2. Reset Source: ctl_amod_g_rst_n
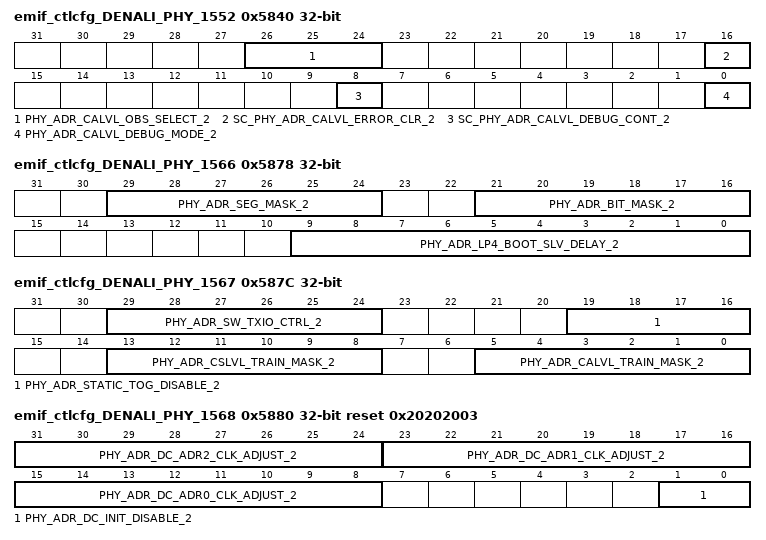
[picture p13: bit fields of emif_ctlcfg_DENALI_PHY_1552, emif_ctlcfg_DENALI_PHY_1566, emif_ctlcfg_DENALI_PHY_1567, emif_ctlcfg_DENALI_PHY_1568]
0x5840 emif_ctlcfg_DENALI_PHY_1552 access per field
  [26:24] PHY_ADR_CALVL_OBS_SELECT_2 rw — CA bit lane to observe result from OBS0 during CA training for address slice 2. Reset Source: ctl_amod_g_rst_n
  [16] SC_PHY_ADR_CALVL_ERROR_CLR_2 wo — Clears the CA training state machine error status for address slice 2. Set to 1 to trigger. WRITE-ONLY Reset Source: ctl_amod_g_rst_n
  [8] SC_PHY_ADR_CALVL_DEBUG_CONT_2 wo — Allows the CA training state machine to advance [when in debug mode] for address slice 2. Set to 1 to trigger. WRITE-ONLY Reset Source: ctl_amod_g_rst_n
  [0] PHY_ADR_CALVL_DEBUG_MODE_2 rw — Enables CA training debug mode for address slice 2. Set to 1 to enable. Reset Source: ctl_amod_g_rst_n
0x5844 emif_ctlcfg_DENALI_PHY_1553 ro
  [31:0] PHY_ADR_CALVL_CH0_OBS0_2 — Observation register for CA training for channel 0 slice 2. READ-ONLY Reset Source: ctl_amod_g_rst_n
0x5848 emif_ctlcfg_DENALI_PHY_1554 ro
  [31:0] PHY_ADR_CALVL_CH1_OBS0_2 — Observation register for CA training for channel 1 slice 2. READ-ONLY Reset Source: ctl_amod_g_rst_n
0x584C emif_ctlcfg_DENALI_PHY_1555 ro
  [31:0] PHY_ADR_CALVL_OBS1_2 — Observation register contains general CA training bits for slice 2. READ-ONLY Reset Source: ctl_amod_g_rst_n
0x5850 emif_ctlcfg_DENALI_PHY_1556 ro reset 0x100
  [31:0] PHY_ADR_CALVL_OBS2_2 — Observation register contains periodic CA training bits for slice 2. READ-ONLY Reset Source: ctl_amod_g_rst_n
0x5854 emif_ctlcfg_DENALI_PHY_1557
  [19:0] PHY_ADR_CALVL_FG_0_2 — CA training foreground pattern 0 for address slice 2. Reset Source: ctl_amod_g_rst_n
0x5858 emif_ctlcfg_DENALI_PHY_1558
  [19:0] PHY_ADR_CALVL_BG_0_2 — CA training background pattern 0 for address slice 2. Reset Source: ctl_amod_g_rst_n
0x585C emif_ctlcfg_DENALI_PHY_1559
  [19:0] PHY_ADR_CALVL_FG_1_2 — CA training foreground pattern 1 for address slice 2. Reset Source: ctl_amod_g_rst_n
0x5860 emif_ctlcfg_DENALI_PHY_1560
  [19:0] PHY_ADR_CALVL_BG_1_2 — CA training background pattern 1 for address slice 2. Reset Source: ctl_amod_g_rst_n
0x5864 emif_ctlcfg_DENALI_PHY_1561
  [19:0] PHY_ADR_CALVL_FG_2_2 — CA training foreground pattern 2 for address slice 2. Reset Source: ctl_amod_g_rst_n
0x5868 emif_ctlcfg_DENALI_PHY_1562
  [19:0] PHY_ADR_CALVL_BG_2_2 — CA training background pattern 2 for address slice 2. Reset Source: ctl_amod_g_rst_n
0x586C emif_ctlcfg_DENALI_PHY_1563
  [19:0] PHY_ADR_CALVL_FG_3_2 — CA training foreground pattern 3 for address slice 2. Reset Source: ctl_amod_g_rst_n
0x5870 emif_ctlcfg_DENALI_PHY_1564
  [19:0] PHY_ADR_CALVL_BG_3_2 — CA training background pattern 3 for address slice 2. Reset Source: ctl_amod_g_rst_n
0x5874 emif_ctlcfg_DENALI_PHY_1565
  [29:0] PHY_ADR_ADDR_SEL_2 — Selects which DFI address pins connect to which CA pins for LPDDR3/4 for address slice 2. Reset Source: ctl_amod_g_rst_n
0x5878 emif_ctlcfg_DENALI_PHY_1566
  [29:24] PHY_ADR_SEG_MASK_2 — Segment mask bit for address slice 2. Set to 1 to indicate that the bit is either CA 4 or CA 9. Reset Source: ctl_amod_g_rst_n
  [21:16] PHY_ADR_BIT_MASK_2 — Mask bit for address slice 2. Set to 1 to indicate that the bit is used. Reset Source: ctl_amod_g_rst_n
  [9:0] PHY_ADR_LP4_BOOT_SLV_DELAY_2 — Address target delay setting during the LPDDR4 boot frequency operation for address slice 2. Reset Source: ctl_amod_g_rst_n
0x587C emif_ctlcfg_DENALI_PHY_1567
  [29:24] PHY_ADR_SW_TXIO_CTRL_2 — Controls address pad output enable for address slice 2. Set to 1 to disable output enable. Reset Source: ctl_amod_g_rst_n
  [19:16] PHY_ADR_STATIC_TOG_DISABLE_2 — Toggle control during static activity for address slice 2. Set bit to dsiable toggling, bit0: Write path delay line, bit1: Read path delay line, bit2: Read data path, bit3: clk_phy, bit4: master delay line. Reset Source: ctl_amod_g_rst_n
  [13:8] PHY_ADR_CSLVL_TRAIN_MASK_2 — Mask bit for CS training participation for address slice 2. Set to 1 to indicate that the bit is participating in CS training. Reset Source: ctl_amod_g_rst_n
  [5:0] PHY_ADR_CALVL_TRAIN_MASK_2 — Mask bit for CA training participation for address slice 2. Set to 1 to indicate that the bit is participating in CA training. Reset Source: ctl_amod_g_rst_n
0x5880 emif_ctlcfg_DENALI_PHY_1568 reset 0x20202003
  [31:24] PHY_ADR_DC_ADR2_CLK_ADJUST_2 — Adjust value of Clock Duty Cycle Adjuster lane 2 for address slice 2. Reset Source: ctl_amod_g_rst_n
  [23:16] PHY_ADR_DC_ADR1_CLK_ADJUST_2 — Adjust value of Clock Duty Cycle Adjuster lane 1 for address slice 2. Reset Source: ctl_amod_g_rst_n
  [15:8] PHY_ADR_DC_ADR0_CLK_ADJUST_2 — Adjust value of Clock Duty Cycle Adjuster lane 0 for address slice 2. Reset Source: ctl_amod_g_rst_n
  [1:0] PHY_ADR_DC_INIT_DISABLE_2 — Duty Cycle Corrector disable at initialization for address slice 2. Set to 1 to disable, bit [1] controls data path, bit [0] controls clock path. Reset Source: ctl_amod_g_rst_n
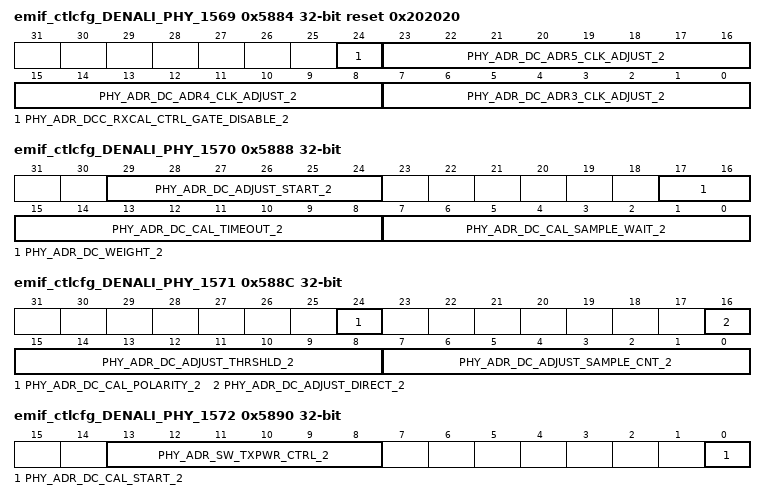
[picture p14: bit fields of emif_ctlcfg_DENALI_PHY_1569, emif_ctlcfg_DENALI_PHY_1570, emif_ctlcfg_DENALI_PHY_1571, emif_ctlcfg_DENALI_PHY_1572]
0x5884 emif_ctlcfg_DENALI_PHY_1569 reset 0x202020
  [24] PHY_ADR_DCC_RXCAL_CTRL_GATE_DISABLE_2 — DCC and RX_CAL clk gate disable for address slice 2. 1 = disable clk gate. Reset Source: ctl_amod_g_rst_n
  [23:16] PHY_ADR_DC_ADR5_CLK_ADJUST_2 — Adjust value of Clock Duty Cycle Adjuster lane 5 for address slice 2. Reset Source: ctl_amod_g_rst_n
  [15:8] PHY_ADR_DC_ADR4_CLK_ADJUST_2 — Adjust value of Clock Duty Cycle Adjuster lane 4 for address slice 2. Reset Source: ctl_amod_g_rst_n
  [7:0] PHY_ADR_DC_ADR3_CLK_ADJUST_2 — Adjust value of Clock Duty Cycle Adjuster lane 3 for address slice 2. Reset Source: ctl_amod_g_rst_n
0x5888 emif_ctlcfg_DENALI_PHY_1570
  [29:24] PHY_ADR_DC_ADJUST_START_2 — DCC calibration starting value for address slice 2. Reset Source: ctl_amod_g_rst_n
  [17:16] PHY_ADR_DC_WEIGHT_2 — DCC weighting factor base value for address slice 2. Reset Source: ctl_amod_g_rst_n
  [15:8] PHY_ADR_DC_CAL_TIMEOUT_2 — DCC number of iterations to wait before timeout for address slice 2. Reset Source: ctl_amod_g_rst_n
  [7:0] PHY_ADR_DC_CAL_SAMPLE_WAIT_2 — DCC cycles to wait after calibration change before sampling results for address slice 2. Reset Source: ctl_amod_g_rst_n
0x588C emif_ctlcfg_DENALI_PHY_1571
  [24] PHY_ADR_DC_CAL_POLARITY_2 — DCC calibration polarity for address slice 2. Reset Source: ctl_amod_g_rst_n
  [16] PHY_ADR_DC_ADJUST_DIRECT_2 — DCC adjust direction for address slice 2. Reset Source: ctl_amod_g_rst_n
  [15:8] PHY_ADR_DC_ADJUST_THRSHLD_2 — DCC adjust threshold around the mid-point for address slice 2. Reset Source: ctl_amod_g_rst_n
  [7:0] PHY_ADR_DC_ADJUST_SAMPLE_CNT_2 — DCC number of samples to take for address slice 2. Reset Source: ctl_amod_g_rst_n
0x5890 emif_ctlcfg_DENALI_PHY_1572
  [13:8] PHY_ADR_SW_TXPWR_CTRL_2 — Disable address output enables in deep sleep mode for address slice 2. Reset Source: ctl_amod_g_rst_n
  [0] PHY_ADR_DC_CAL_START_2 — DCC Manual trigger for address slice 2. Reset Source: ctl_amod_g_rst_n
